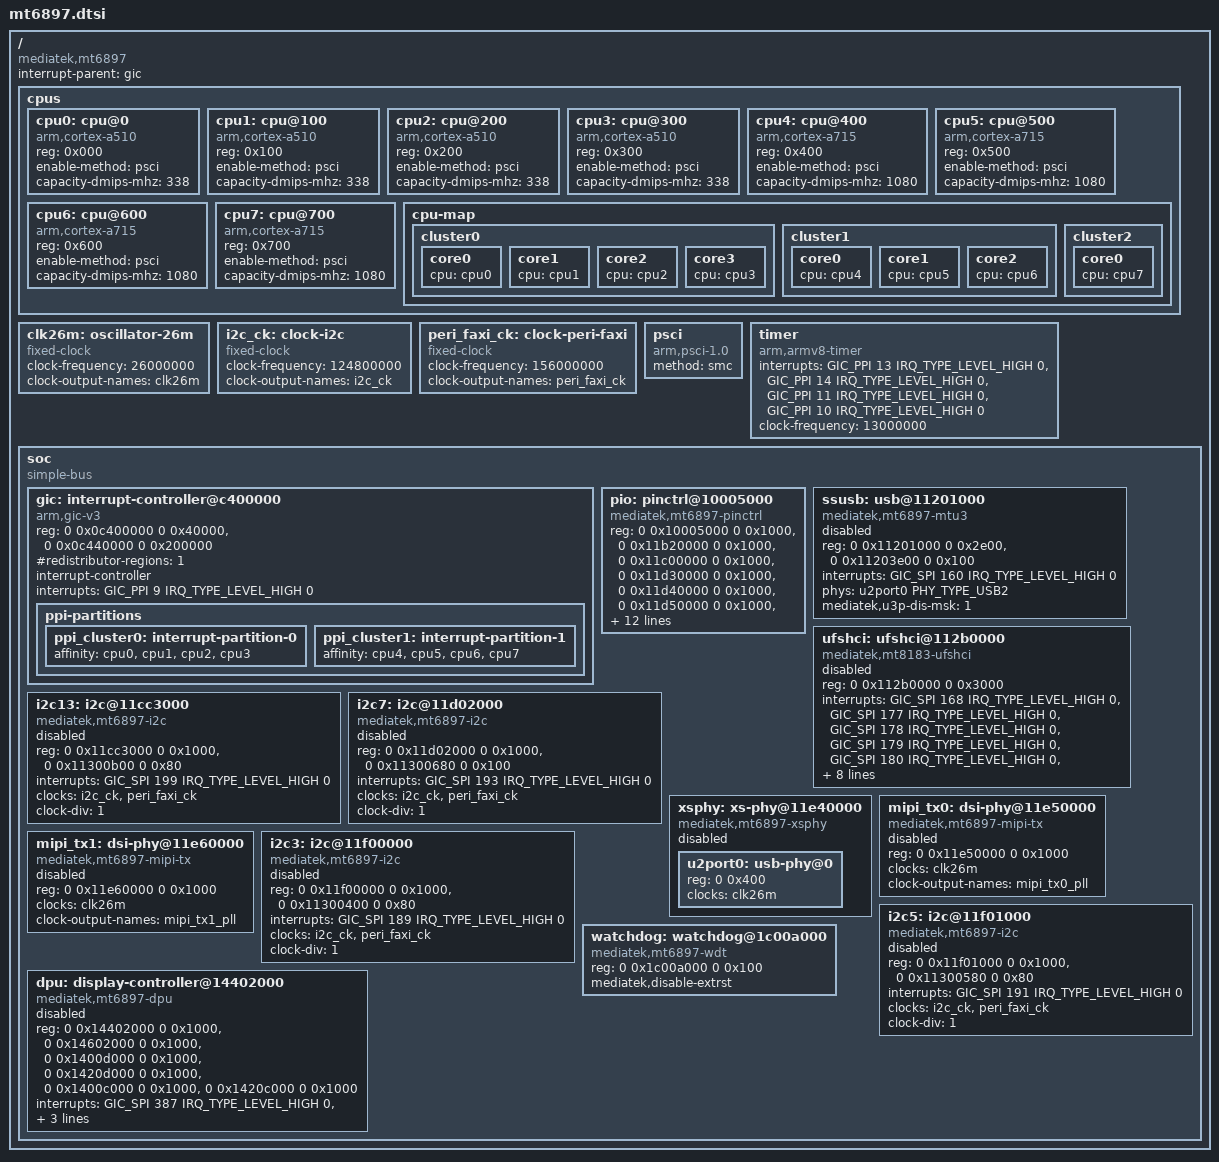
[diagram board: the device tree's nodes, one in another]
// SPDX-License-Identifier: (GPL-2.0-only OR MIT)
/*
 * MediaTek MT6897 (Dimensity 8300)
 *
 * Clocks, power domains and regulators are left as the bootloader set
 * them up until this SoC has drivers for them.
 */

#include <dt-bindings/interrupt-controller/arm-gic.h>
#include <dt-bindings/interrupt-controller/irq.h>
#include <dt-bindings/phy/phy.h>

/ {
	compatible = "mediatek,mt6897";
	interrupt-parent = <&gic>;
	#address-cells = <2>;
	#size-cells = <2>;

	cpus {
		#address-cells = <1>;
		#size-cells = <0>;

		cpu0: cpu@0 {
			device_type = "cpu";
			compatible = "arm,cortex-a510";
			reg = <0x000>;
			enable-method = "psci";
			capacity-dmips-mhz = <338>;
		};

		cpu1: cpu@100 {
			device_type = "cpu";
			compatible = "arm,cortex-a510";
			reg = <0x100>;
			enable-method = "psci";
			capacity-dmips-mhz = <338>;
		};

		cpu2: cpu@200 {
			device_type = "cpu";
			compatible = "arm,cortex-a510";
			reg = <0x200>;
			enable-method = "psci";
			capacity-dmips-mhz = <338>;
		};

		cpu3: cpu@300 {
			device_type = "cpu";
			compatible = "arm,cortex-a510";
			reg = <0x300>;
			enable-method = "psci";
			capacity-dmips-mhz = <338>;
		};

		cpu4: cpu@400 {
			device_type = "cpu";
			compatible = "arm,cortex-a715";
			reg = <0x400>;
			enable-method = "psci";
			capacity-dmips-mhz = <1080>;
		};

		cpu5: cpu@500 {
			device_type = "cpu";
			compatible = "arm,cortex-a715";
			reg = <0x500>;
			enable-method = "psci";
			capacity-dmips-mhz = <1080>;
		};

		cpu6: cpu@600 {
			device_type = "cpu";
			compatible = "arm,cortex-a715";
			reg = <0x600>;
			enable-method = "psci";
			capacity-dmips-mhz = <1080>;
		};

		cpu7: cpu@700 {
			device_type = "cpu";
			compatible = "arm,cortex-a715";
			reg = <0x700>;
			enable-method = "psci";
			capacity-dmips-mhz = <1080>;
		};

		cpu-map {
			cluster0 {
				core0 {
					cpu = <&cpu0>;
				};

				core1 {
					cpu = <&cpu1>;
				};

				core2 {
					cpu = <&cpu2>;
				};

				core3 {
					cpu = <&cpu3>;
				};
			};

			cluster1 {
				core0 {
					cpu = <&cpu4>;
				};

				core1 {
					cpu = <&cpu5>;
				};

				core2 {
					cpu = <&cpu6>;
				};
			};

			cluster2 {
				core0 {
					cpu = <&cpu7>;
				};
			};
		};
	};

	clk26m: oscillator-26m {
		compatible = "fixed-clock";
		#clock-cells = <0>;
		clock-frequency = <26000000>;
		clock-output-names = "clk26m";
	};

	/* The rates the bootloader sets, until topckgen has a driver. */
	i2c_ck: clock-i2c {
		compatible = "fixed-clock";
		#clock-cells = <0>;
		clock-frequency = <124800000>;
		clock-output-names = "i2c_ck";
	};

	peri_faxi_ck: clock-peri-faxi {
		compatible = "fixed-clock";
		#clock-cells = <0>;
		clock-frequency = <156000000>;
		clock-output-names = "peri_faxi_ck";
	};

	psci {
		compatible = "arm,psci-1.0";
		method = "smc";
	};

	timer {
		compatible = "arm,armv8-timer";
		interrupts = <GIC_PPI 13 IRQ_TYPE_LEVEL_HIGH 0>,
			     <GIC_PPI 14 IRQ_TYPE_LEVEL_HIGH 0>,
			     <GIC_PPI 11 IRQ_TYPE_LEVEL_HIGH 0>,
			     <GIC_PPI 10 IRQ_TYPE_LEVEL_HIGH 0>;
		clock-frequency = <13000000>;
	};

	soc {
		compatible = "simple-bus";
		#address-cells = <2>;
		#size-cells = <2>;
		ranges;

		gic: interrupt-controller@c400000 {
			compatible = "arm,gic-v3";
			reg = <0 0x0c400000 0 0x40000>,
			      <0 0x0c440000 0 0x200000>;
			#interrupt-cells = <4>;
			#redistributor-regions = <1>;
			interrupt-controller;
			interrupts = <GIC_PPI 9 IRQ_TYPE_LEVEL_HIGH 0>;

			ppi-partitions {
				ppi_cluster0: interrupt-partition-0 {
					affinity = <&cpu0 &cpu1 &cpu2 &cpu3>;
				};

				ppi_cluster1: interrupt-partition-1 {
					affinity = <&cpu4 &cpu5 &cpu6 &cpu7>;
				};
			};
		};

		pio: pinctrl@10005000 {
			compatible = "mediatek,mt6897-pinctrl";
			reg = <0 0x10005000 0 0x1000>,
			      <0 0x11b20000 0 0x1000>,
			      <0 0x11c00000 0 0x1000>,
			      <0 0x11d30000 0 0x1000>,
			      <0 0x11d40000 0 0x1000>,
			      <0 0x11d50000 0 0x1000>,
			      <0 0x11ea0000 0 0x1000>,
			      <0 0x11eb0000 0 0x1000>,
			      <0 0x11f20000 0 0x1000>,
			      <0 0x11f30000 0 0x1000>,
			      <0 0x11ce0000 0 0x1000>,
			      <0 0x11de0000 0 0x1000>,
			      <0 0x11e90000 0 0x1000>,
			      <0 0x11fe0000 0 0x1000>,
			      <0 0x1c01e000 0 0x1000>;
			reg-names = "base", "rt", "rm", "bl", "bm", "br", "lb", "lt",
				    "tm", "tl", "eint0", "eint1", "eint2", "eint3",
				    "eint4";
			gpio-controller;
			#gpio-cells = <2>;
			gpio-ranges = <&pio 0 0 232>;
			interrupt-controller;
			interrupts = <GIC_SPI 309 IRQ_TYPE_LEVEL_HIGH 0>;
			#interrupt-cells = <2>;
		};

		ssusb: usb@11201000 {
			compatible = "mediatek,mt6897-mtu3", "mediatek,mtu3";
			reg = <0 0x11201000 0 0x2e00>, <0 0x11203e00 0 0x100>;
			reg-names = "mac", "ippc";
			interrupts = <GIC_SPI 160 IRQ_TYPE_LEVEL_HIGH 0>;
			phys = <&u2port0 PHY_TYPE_USB2>;
			/* The USB3 port needs the Type-C mux, which has no driver yet. */
			mediatek,u3p-dis-msk = <1>;
			status = "disabled";
		};

		ufshci: ufshci@112b0000 {
			compatible = "mediatek,mt8183-ufshci";
			reg = <0 0x112b0000 0 0x3000>;
			interrupts = <GIC_SPI 168 IRQ_TYPE_LEVEL_HIGH 0>,
				     <GIC_SPI 177 IRQ_TYPE_LEVEL_HIGH 0>,
				     <GIC_SPI 178 IRQ_TYPE_LEVEL_HIGH 0>,
				     <GIC_SPI 179 IRQ_TYPE_LEVEL_HIGH 0>,
				     <GIC_SPI 180 IRQ_TYPE_LEVEL_HIGH 0>,
				     <GIC_SPI 181 IRQ_TYPE_LEVEL_HIGH 0>,
				     <GIC_SPI 182 IRQ_TYPE_LEVEL_HIGH 0>,
				     <GIC_SPI 183 IRQ_TYPE_LEVEL_HIGH 0>,
				     <GIC_SPI 184 IRQ_TYPE_LEVEL_HIGH 0>;
			mediatek,ufs-pmc-via-fastauto;
			mediatek,ufs-tx-skew-fix;
			mediatek,ufs-broken-rtc;
			mediatek,ufs-rtff-mtcmos;
			status = "disabled";
		};

		i2c13: i2c@11cc3000 {
			compatible = "mediatek,mt6897-i2c", "mediatek,mt8188-i2c";
			reg = <0 0x11cc3000 0 0x1000>, <0 0x11300b00 0 0x80>;
			interrupts = <GIC_SPI 199 IRQ_TYPE_LEVEL_HIGH 0>;
			clocks = <&i2c_ck>, <&peri_faxi_ck>;
			clock-names = "main", "dma";
			clock-div = <1>;
			#address-cells = <1>;
			#size-cells = <0>;
			status = "disabled";
		};

		i2c7: i2c@11d02000 {
			compatible = "mediatek,mt6897-i2c", "mediatek,mt8188-i2c";
			reg = <0 0x11d02000 0 0x1000>, <0 0x11300680 0 0x100>;
			interrupts = <GIC_SPI 193 IRQ_TYPE_LEVEL_HIGH 0>;
			clocks = <&i2c_ck>, <&peri_faxi_ck>;
			clock-names = "main", "dma";
			clock-div = <1>;
			#address-cells = <1>;
			#size-cells = <0>;
			status = "disabled";
		};

		xsphy: xs-phy@11e40000 {
			compatible = "mediatek,mt6897-xsphy", "mediatek,xsphy";
			#address-cells = <1>;
			#size-cells = <1>;
			ranges = <0 0 0x11e40000 0x1000>;
			status = "disabled";

			u2port0: usb-phy@0 {
				reg = <0 0x400>;
				clocks = <&clk26m>;
				clock-names = "ref";
				#phy-cells = <1>;
			};
		};

		mipi_tx0: dsi-phy@11e50000 {
			compatible = "mediatek,mt6897-mipi-tx",
				     "mediatek,mt8196-mipi-tx";
			reg = <0 0x11e50000 0 0x1000>;
			clocks = <&clk26m>;
			clock-output-names = "mipi_tx0_pll";
			#clock-cells = <0>;
			#phy-cells = <0>;
			status = "disabled";
		};

		mipi_tx1: dsi-phy@11e60000 {
			compatible = "mediatek,mt6897-mipi-tx",
				     "mediatek,mt8196-mipi-tx";
			reg = <0 0x11e60000 0 0x1000>;
			clocks = <&clk26m>;
			clock-output-names = "mipi_tx1_pll";
			#clock-cells = <0>;
			#phy-cells = <0>;
			status = "disabled";
		};

		i2c3: i2c@11f00000 {
			compatible = "mediatek,mt6897-i2c", "mediatek,mt8188-i2c";
			reg = <0 0x11f00000 0 0x1000>, <0 0x11300400 0 0x80>;
			interrupts = <GIC_SPI 189 IRQ_TYPE_LEVEL_HIGH 0>;
			clocks = <&i2c_ck>, <&peri_faxi_ck>;
			clock-names = "main", "dma";
			clock-div = <1>;
			#address-cells = <1>;
			#size-cells = <0>;
			status = "disabled";
		};

		i2c5: i2c@11f01000 {
			compatible = "mediatek,mt6897-i2c", "mediatek,mt8188-i2c";
			reg = <0 0x11f01000 0 0x1000>, <0 0x11300580 0 0x80>;
			interrupts = <GIC_SPI 191 IRQ_TYPE_LEVEL_HIGH 0>;
			clocks = <&i2c_ck>, <&peri_faxi_ck>;
			clock-names = "main", "dma";
			clock-div = <1>;
			#address-cells = <1>;
			#size-cells = <0>;
			status = "disabled";
		};

		dpu: display-controller@14402000 {
			compatible = "mediatek,mt6897-dpu";
			reg = <0 0x14402000 0 0x1000>, <0 0x14602000 0 0x1000>,
			      <0 0x1400d000 0 0x1000>, <0 0x1420d000 0 0x1000>,
			      <0 0x1400c000 0 0x1000>, <0 0x1420c000 0 0x1000>;
			reg-names = "ovl0", "ovl1", "dsi0", "dsi1", "dsc0", "dsc1";
			interrupts = <GIC_SPI 387 IRQ_TYPE_LEVEL_HIGH 0>,
				     <GIC_SPI 431 IRQ_TYPE_LEVEL_HIGH 0>;
			interrupt-names = "ovl0", "ovl1";
			clocks = <&mipi_tx0>, <&mipi_tx1>;
			clock-names = "dsi0-hs", "dsi1-hs";
			phys = <&mipi_tx0>, <&mipi_tx1>;
			phy-names = "dsi0", "dsi1";
			#address-cells = <1>;
			#size-cells = <0>;
			status = "disabled";
		};

		watchdog: watchdog@1c00a000 {
			compatible = "mediatek,mt6897-wdt", "mediatek,mt6589-wdt";
			reg = <0 0x1c00a000 0 0x100>;
			/* An external reset cuts the power to RAM and loses pstore. */
			mediatek,disable-extrst;
		};
	};
};
